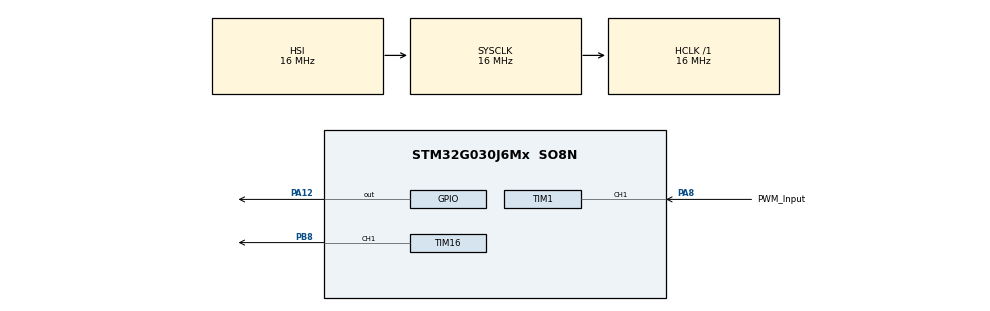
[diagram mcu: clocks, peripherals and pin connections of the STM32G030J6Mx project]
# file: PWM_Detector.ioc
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Mcu.Family=STM32G0
Mcu.Name=STM32G030J6Mx
Mcu.Package=SO8N
NRST__PA0__PA1__PA2.StandardMode=true
NVIC.TIM1_CC_IRQn=true\:0\:0\:false\:false\:true\:true\:true\:true
PA12\ [PA10].GPIO_PuPd=GPIO_PULLDOWN
PA12\ [PA10].Signal=GPIO_Output
PA14-BOOT0__PA15__PB5__PB6.StandardMode=true
PA8.GPIO_Label=PWM_Input
PA8.GPIO_PuPd=GPIO_PULLDOWN
PA8.Signal=S_TIM1_CH1
PB0__PB1__PA8__PA11\ [PA9].StandardMode=true
PB8.Signal=S_TIM16_CH1
PC14-OSC32_IN\ (PC14)__PB7__PB8__PB9.StandardMode=true
ProjectManager.HeapSize=0x200
ProjectManager.StackSize=0x400
ProjectManager.TargetToolchain=STM32CubeIDE
RCC.AHBFreq_Value=16000000
RCC.CortexFreq_Value=16000000
RCC.EXTERNAL_CLOCK_VALUE=12288000
RCC.HCLKFreq_Value=16000000
RCC.HSE_VALUE=8000000
RCC.HSI_VALUE=16000000
RCC.LSE_VALUE=32768
RCC.SYSCLKFreq_VALUE=16000000
RCC.VCOOutputFreq_Value=128000000
SH.S_TIM16_CH1.0=TIM16_CH1,PWM Generation1 CH1
SH.S_TIM1_CH1.0=TIM1_CH1,PWM_Input_1
TIM16.Channel=TIM_CHANNEL_1
TIM16.Period=2000-1
TIM16.Prescaler=16-1
VP_TIM16_VS_ClockSourceINT.Mode=Enable_Timer
VP_TIM1_VS_ClockSourceINT.Mode=Internal
board=custom

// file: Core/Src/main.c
/* USER CODE BEGIN Header */
/**
  ******************************************************************************
  * @file           : main.c
  * @brief          : Main program body
  ******************************************************************************
  * @attention
  *
  * Copyright (c) 2024 STMicroelectronics.
  * All rights reserved.
  *
  * This software is licensed under terms that can be found in the LICENSE file
  * in the root directory of this software component.
  * If no LICENSE file comes with this software, it is provided AS-IS.
  *
  ******************************************************************************
  */
/* USER CODE END Header */
#include "main.h"

TIM_HandleTypeDef htim1;
TIM_HandleTypeDef htim16;

/* USER CODE BEGIN PV */
uint32_t ICValue =0;
uint32_t Frequency =0;
float Duty = 0.0;

/* USER CODE END PV */

void SystemClock_Config(void);
static void MX_GPIO_Init(void);
static void MX_TIM1_Init(void);
static void MX_TIM16_Init(void);
/* USER CODE BEGIN PFP */
//static voqid MX_NVIC_Init(void);
/* USER CODE END PFP */

/* USER CODE BEGIN 0 */
void HAL_TIM_IC_CaptureCallback(TIM_HandleTypeDef *htim)
{
	if (htim->Channel == HAL_TIM_ACTIVE_CHANNEL_1)  // If the interrupt is triggered by channel 1
	{
		// Read the IC value
		ICValue = HAL_TIM_ReadCapturedValue(htim, TIM_CHANNEL_1);

		if (ICValue != 0)
		{
			// calculate the Duty Cycle
			Duty = (HAL_TIM_ReadCapturedValue(htim, TIM_CHANNEL_2) *100)/ICValue;

			//Set and Reset the PA12
			if (Duty >= 40 && Duty <= 50) {
			    // Check if GPIOA_PIN_12 is already set
			    if (HAL_GPIO_ReadPin(GPIOA, GPIO_PIN_12) == GPIO_PIN_RESET) {
			        HAL_GPIO_WritePin(GPIOA, GPIO_PIN_12, GPIO_PIN_SET);
			    }
			} else {
			    // Check if GPIOA_PIN_12 is already reset
			    if (HAL_GPIO_ReadPin(GPIOA, GPIO_PIN_12) == GPIO_PIN_SET) {
			        HAL_GPIO_WritePin(GPIOA, GPIO_PIN_12, GPIO_PIN_RESET);
			    }
			}

			Frequency = 16000000/ICValue;
		}
	}
}
/* USER CODE END 0 */

int main(void)
{

  /* MCU Configuration--------------------------------------------------------*/

  /* Reset of all peripherals, Initializes the Flash interface and the Systick. */
  HAL_Init();

  /* Configure the system clock */
  SystemClock_Config();

  /* Initialize all configured peripherals */
  MX_GPIO_Init();
  MX_TIM1_Init();
  MX_TIM16_Init();
  /* USER CODE BEGIN 2 */
//  MX_NVIC_Init();

  HAL_TIM_IC_Start_IT(&htim1, TIM_CHANNEL_1);   // Pulse start channel
  HAL_TIM_IC_Start(&htim1, TIM_CHANNEL_2);   	// Duty End channel
  TIM16->CCR1 = 900; // Set CCR1 to 900 so the Duty = 45%
  HAL_TIM_PWM_Start(&htim16, TIM_CHANNEL_1); // Start PWM

  /* USER CODE END 2 */

  /* Infinite loop */
  while (1)
  {

  }
}

void SystemClock_Config(void)
{
  RCC_OscInitTypeDef RCC_OscInitStruct = {0};
  RCC_ClkInitTypeDef RCC_ClkInitStruct = {0};

  /** Configure the main internal regulator output voltage
  */
  HAL_PWREx_ControlVoltageScaling(PWR_REGULATOR_VOLTAGE_SCALE1);

  /** Initializes the RCC Oscillators according to the specified parameters
  * in the RCC_OscInitTypeDef structure.
  */
  RCC_OscInitStruct.OscillatorType = RCC_OSCILLATORTYPE_HSI;
  RCC_OscInitStruct.HSIState = RCC_HSI_ON;
  RCC_OscInitStruct.HSIDiv = RCC_HSI_DIV1;
  RCC_OscInitStruct.HSICalibrationValue = RCC_HSICALIBRATION_DEFAULT;
  RCC_OscInitStruct.PLL.PLLState = RCC_PLL_NONE;
  if (HAL_RCC_OscConfig(&RCC_OscInitStruct) != HAL_OK)
  {
    Error_Handler();
  }

  /** Initializes the CPU, AHB and APB buses clocks
  */
  RCC_ClkInitStruct.ClockType = RCC_CLOCKTYPE_HCLK|RCC_CLOCKTYPE_SYSCLK
                              |RCC_CLOCKTYPE_PCLK1;
  RCC_ClkInitStruct.SYSCLKSource = RCC_SYSCLKSOURCE_HSI;
  RCC_ClkInitStruct.AHBCLKDivider = RCC_SYSCLK_DIV1;
  RCC_ClkInitStruct.APB1CLKDivider = RCC_HCLK_DIV1;

  if (HAL_RCC_ClockConfig(&RCC_ClkInitStruct, FLASH_LATENCY_0) != HAL_OK)
  {
    Error_Handler();
  }
}

static void MX_TIM1_Init(void)
{

  TIM_ClockConfigTypeDef sClockSourceConfig = {0};
  TIM_SlaveConfigTypeDef sSlaveConfig = {0};
  TIM_IC_InitTypeDef sConfigIC = {0};
  TIM_MasterConfigTypeDef sMasterConfig = {0};

  htim1.Instance = TIM1;
  htim1.Init.Prescaler = 0;
  htim1.Init.CounterMode = TIM_COUNTERMODE_UP;
  htim1.Init.Period = 65535;
  htim1.Init.ClockDivision = TIM_CLOCKDIVISION_DIV1;
  htim1.Init.RepetitionCounter = 0;
  htim1.Init.AutoReloadPreload = TIM_AUTORELOAD_PRELOAD_DISABLE;
  if (HAL_TIM_Base_Init(&htim1) != HAL_OK)
  {
    Error_Handler();
  }
  sClockSourceConfig.ClockSource = TIM_CLOCKSOURCE_INTERNAL;
  if (HAL_TIM_ConfigClockSource(&htim1, &sClockSourceConfig) != HAL_OK)
  {
    Error_Handler();
  }
  if (HAL_TIM_IC_Init(&htim1) != HAL_OK)
  {
    Error_Handler();
  }
  sSlaveConfig.SlaveMode = TIM_SLAVEMODE_RESET;
  sSlaveConfig.InputTrigger = TIM_TS_TI1FP1;
  sSlaveConfig.TriggerPolarity = TIM_INPUTCHANNELPOLARITY_RISING;
  sSlaveConfig.TriggerPrescaler = TIM_ICPSC_DIV1;
  sSlaveConfig.TriggerFilter = 0;
  if (HAL_TIM_SlaveConfigSynchro(&htim1, &sSlaveConfig) != HAL_OK)
  {
    Error_Handler();
  }
  sConfigIC.ICPolarity = TIM_INPUTCHANNELPOLARITY_RISING;
  sConfigIC.ICSelection = TIM_ICSELECTION_DIRECTTI;
  sConfigIC.ICPrescaler = TIM_ICPSC_DIV1;
  sConfigIC.ICFilter = 0;
  if (HAL_TIM_IC_ConfigChannel(&htim1, &sConfigIC, TIM_CHANNEL_1) != HAL_OK)
  {
    Error_Handler();
  }
  sConfigIC.ICPolarity = TIM_INPUTCHANNELPOLARITY_FALLING;
  sConfigIC.ICSelection = TIM_ICSELECTION_INDIRECTTI;
  if (HAL_TIM_IC_ConfigChannel(&htim1, &sConfigIC, TIM_CHANNEL_2) != HAL_OK)
  {
    Error_Handler();
  }
  sMasterConfig.MasterOutputTrigger = TIM_TRGO_RESET;
  sMasterConfig.MasterOutputTrigger2 = TIM_TRGO2_RESET;
  sMasterConfig.MasterSlaveMode = TIM_MASTERSLAVEMODE_DISABLE;
  if (HAL_TIMEx_MasterConfigSynchronization(&htim1, &sMasterConfig) != HAL_OK)
  {
    Error_Handler();
  }

}

static void MX_TIM16_Init(void)
{

  TIM_OC_InitTypeDef sConfigOC = {0};
  TIM_BreakDeadTimeConfigTypeDef sBreakDeadTimeConfig = {0};

  htim16.Instance = TIM16;
  htim16.Init.Prescaler = 16-1;
  htim16.Init.CounterMode = TIM_COUNTERMODE_UP;
  htim16.Init.Period = 2000-1;
  htim16.Init.ClockDivision = TIM_CLOCKDIVISION_DIV1;
  htim16.Init.RepetitionCounter = 0;
  htim16.Init.AutoReloadPreload = TIM_AUTORELOAD_PRELOAD_DISABLE;
  if (HAL_TIM_Base_Init(&htim16) != HAL_OK)
  {
    Error_Handler();
  }
  if (HAL_TIM_PWM_Init(&htim16) != HAL_OK)
  {
    Error_Handler();
  }
  sConfigOC.OCMode = TIM_OCMODE_PWM1;
  sConfigOC.Pulse = 0;
  sConfigOC.OCPolarity = TIM_OCPOLARITY_HIGH;
  sConfigOC.OCNPolarity = TIM_OCNPOLARITY_HIGH;
  sConfigOC.OCFastMode = TIM_OCFAST_DISABLE;
  sConfigOC.OCIdleState = TIM_OCIDLESTATE_RESET;
  sConfigOC.OCNIdleState = TIM_OCNIDLESTATE_RESET;
  if (HAL_TIM_PWM_ConfigChannel(&htim16, &sConfigOC, TIM_CHANNEL_1) != HAL_OK)
  {
    Error_Handler();
  }
  sBreakDeadTimeConfig.OffStateRunMode = TIM_OSSR_DISABLE;
  sBreakDeadTimeConfig.OffStateIDLEMode = TIM_OSSI_DISABLE;
  sBreakDeadTimeConfig.LockLevel = TIM_LOCKLEVEL_OFF;
  sBreakDeadTimeConfig.DeadTime = 0;
  sBreakDeadTimeConfig.BreakState = TIM_BREAK_DISABLE;
  sBreakDeadTimeConfig.BreakPolarity = TIM_BREAKPOLARITY_HIGH;
  sBreakDeadTimeConfig.BreakFilter = 0;
  sBreakDeadTimeConfig.AutomaticOutput = TIM_AUTOMATICOUTPUT_DISABLE;
  if (HAL_TIMEx_ConfigBreakDeadTime(&htim16, &sBreakDeadTimeConfig) != HAL_OK)
  {
    Error_Handler();
  }
  HAL_TIM_MspPostInit(&htim16);

}

static void MX_GPIO_Init(void)
{
  GPIO_InitTypeDef GPIO_InitStruct = {0};

  /* GPIO Ports Clock Enable */
  __HAL_RCC_GPIOB_CLK_ENABLE();
  __HAL_RCC_GPIOA_CLK_ENABLE();

  /*Configure GPIO pin Output Level */
  HAL_GPIO_WritePin(GPIOA, GPIO_PIN_12, GPIO_PIN_RESET);

  /*Configure GPIO pin : PA12 */
  GPIO_InitStruct.Pin = GPIO_PIN_12;
  GPIO_InitStruct.Mode = GPIO_MODE_OUTPUT_PP;
  GPIO_InitStruct.Pull = GPIO_PULLDOWN;
  GPIO_InitStruct.Speed = GPIO_SPEED_FREQ_LOW;
  HAL_GPIO_Init(GPIOA, &GPIO_InitStruct);

}

void Error_Handler(void)
{
  __disable_irq();
  while (1)
  {
  }
}
